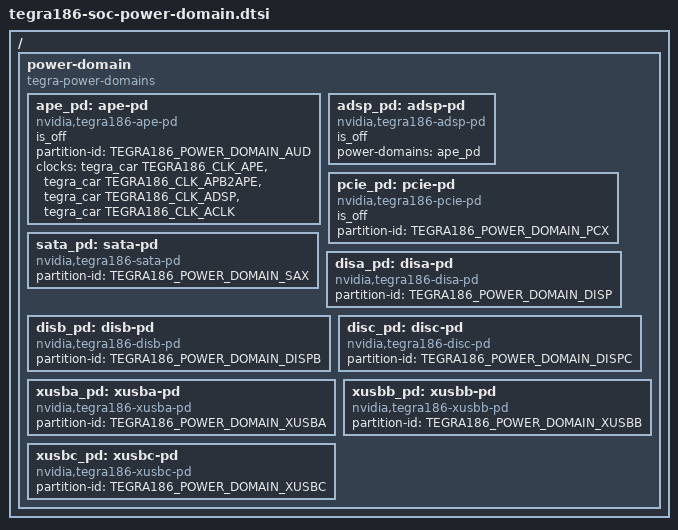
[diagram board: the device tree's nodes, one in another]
/*
 * Copyright (c) 2020, NVIDIA CORPORATION.  All rights reserved.
 *
 * This program is free software; you can redistribute it and/or modify it
 * under the terms and conditions of the GNU General Public License,
 * version 2, as published by the Free Software Foundation.
 *
 * This program is distributed in the hope it will be useful, but WITHOUT
 * ANY WARRANTY; without even the implied warranty of MERCHANTABILITY or
 * FITNESS FOR A PARTICULAR PURPOSE.  See the GNU General Public License for
 * more details.
 *
 * You should have received a copy of the GNU General Public License
 * along with this program.  If not, see <http://www.gnu.org/licenses/>.
 */

/ {
	power-domain {
		compatible = "tegra-power-domains";

		ape_pd: ape-pd {
			compatible = "nvidia,tegra186-ape-pd";
			is_off;
			#power-domain-cells = <0>;
			partition-id = <TEGRA186_POWER_DOMAIN_AUD>;
			clocks = <&tegra_car TEGRA186_CLK_APE>,
				<&tegra_car TEGRA186_CLK_APB2APE>,
				<&tegra_car TEGRA186_CLK_ADSP>,
				<&tegra_car TEGRA186_CLK_ACLK>;
			clock-names = "ape", "apb2ape", "adsp", "aclk";
		};

		adsp_pd: adsp-pd {
			compatible = "nvidia,tegra186-adsp-pd";
			is_off;
			#power-domain-cells = <0>;
			power-domains = <&ape_pd>;
		};

		pcie_pd: pcie-pd {
			compatible = "nvidia,tegra186-pcie-pd";
			is_off;
			#power-domain-cells = <0>;
			partition-id = <TEGRA186_POWER_DOMAIN_PCX>;
		};

		sata_pd: sata-pd {
			compatible = "nvidia,tegra186-sata-pd";
			#power-domain-cells = <0>;
			partition-id = <TEGRA186_POWER_DOMAIN_SAX>;
		};

		disa_pd: disa-pd {
			compatible = "nvidia,tegra186-disa-pd";
			#power-domain-cells = <0>;
			partition-id = <TEGRA186_POWER_DOMAIN_DISP>;
		};

		disb_pd: disb-pd {
			compatible = "nvidia,tegra186-disb-pd";
			#power-domain-cells = <0>;
			partition-id = <TEGRA186_POWER_DOMAIN_DISPB>;
		};

		disc_pd: disc-pd {
			compatible = "nvidia,tegra186-disc-pd";
			#power-domain-cells = <0>;
			partition-id = <TEGRA186_POWER_DOMAIN_DISPC>;
		};

		xusba_pd: xusba-pd {
			compatible = "nvidia,tegra186-xusba-pd";
			#power-domain-cells = <0>;
			partition-id = <TEGRA186_POWER_DOMAIN_XUSBA>;
		};

		xusbb_pd: xusbb-pd {
			compatible = "nvidia,tegra186-xusbb-pd";
			#power-domain-cells = <0>;
			partition-id = <TEGRA186_POWER_DOMAIN_XUSBB>;
		};

		xusbc_pd: xusbc-pd {
			compatible = "nvidia,tegra186-xusbc-pd";
			#power-domain-cells = <0>;
			partition-id = <TEGRA186_POWER_DOMAIN_XUSBC>;
		};
	};
};

